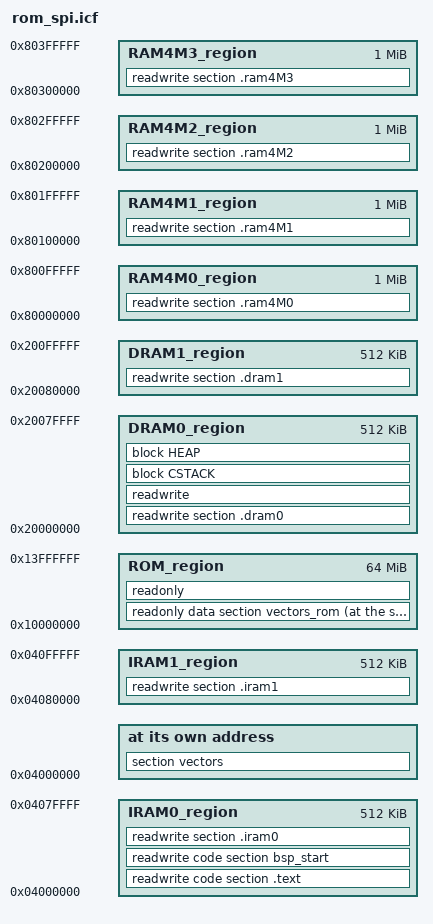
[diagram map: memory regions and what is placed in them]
/*###ICF### Section handled by ICF editor, don't touch! ****/
/*-Editor annotation file-*/
/* IcfEditorFile="$TOOLKIT_DIR$\config\ide\IcfEditor\cortex_v1_0.xml" */
/*-Specials-*/
define symbol __ICFEDIT_intvec_start__ = 0x04000000;
/*-Memory Regions-*/
define symbol __ICFEDIT_region_ROM_start__ = 0x00000000;
define symbol __ICFEDIT_region_ROM_end__   = 0x00000000;
define symbol __ICFEDIT_region_RAM_start__ = 0x00000000;
define symbol __ICFEDIT_region_RAM_end__   = 0x00000000;
/*-Sizes-*/
define symbol __ICFEDIT_size_cstack__ = 0x8000;
define symbol __ICFEDIT_size_heap__   = 0x8000;
/**** End of ICF editor section. ###ICF###*/

/*============================================================================*/
/* M E M O R Y   R E G I O N                                                  */
/*============================================================================*/
define memory mem with size = 4G;

define region IRAM0_region   = mem:[from 0x04000000 size 512K];
define region IRAM1_region   = mem:[from 0x04080000 size 512K];

define region DRAM0_region   = mem:[from 0x20000000 size 512K];
define region DRAM1_region   = mem:[from 0x20080000 size 512K];

define region RAM4M0_region  = mem:[from 0x80000000 size   1M];
define region RAM4M1_region  = mem:[from 0x80100000 size   1M];
define region RAM4M2_region  = mem:[from 0x80200000 size   1M];
define region RAM4M3_region  = mem:[from 0x80300000 size   1M];

define region ROM_region     = mem:[from 0x10000000 size  64M];


/*============================================================================*/
/* B L O C K   L A Y O U T                                                    */
/*============================================================================*/
define block CSTACK    with alignment = 8, size = __ICFEDIT_size_cstack__   { };
define block HEAP      with alignment = 8, size = __ICFEDIT_size_heap__     { };

do not initialize  { section .noinit };
initialize by copy { readwrite, readonly }
            except { section vectors_rom, 
                     section .text object system_RZN1.o, 
                     symbol __iar_program_start,
                     symbol __iar_*_init3 };


/*============================================================================*/
/* S E C T I O N   L A Y O U T                                                */
/*============================================================================*/
place at address mem:__ICFEDIT_intvec_start__ {section vectors};
place in IRAM0_region   {readwrite code section .text,
                         readwrite code section bsp_start};

place in IRAM0_region   {readwrite section .iram0};
place in IRAM1_region   {readwrite section .iram1};

place in DRAM0_region   {readwrite section .dram0};
place in DRAM0_region   {readwrite, block CSTACK, block HEAP};
place in DRAM1_region   {readwrite section .dram1};

place in RAM4M0_region  {readwrite section .ram4M0};
place in RAM4M1_region  {readwrite section .ram4M1};
place in RAM4M2_region  {readwrite section .ram4M2};
place in RAM4M3_region  {readwrite section .ram4M3};

place at start of ROM_region {readonly data section vectors_rom};
place in ROM_region     {readonly};
